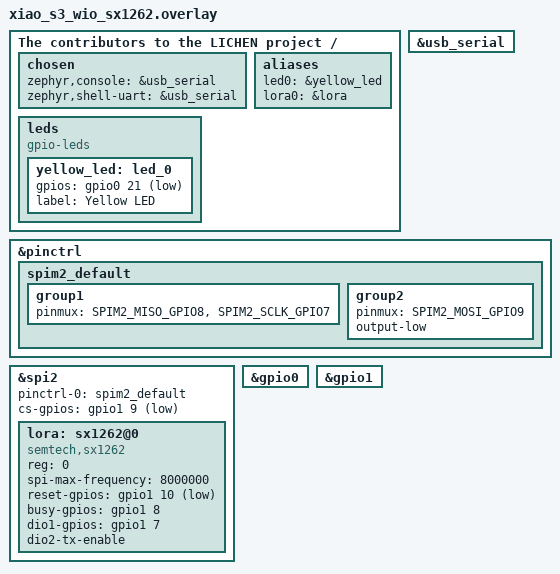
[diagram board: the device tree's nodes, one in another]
# SPDX-License-Identifier: GPL-3.0-or-later
# SPDX-FileCopyrightText: The contributors to the LICHEN project
/*
 * RETIRED/BLOCKED per project-LICHEN-2u26.10 (m5m1.8 bridge audit, project-LICHEN-p70q/worktree-worker18): Seeed XIAO ESP32-S3 + Wio-SX1262 has no canonical Zephyr board target. xiao_s3_wio_sx1262 invalid -b target. Classified FAIL; support removed. Use heltec_wifi_lora32_v3_esp32s3_procpu proxy. Fragment retained for reference only. See docs/firmware-board-capability-matrix.md.
 *
 * Original pin map (for reference):
 * ESP32-S3 + SX1262 LoRa (via B2B connector)
 * SX1262 SPI: SCK=GPIO7, MISO=GPIO8, MOSI=GPIO9, NSS=GPIO41
 * Control: RESET=GPIO42, BUSY=GPIO40, DIO1=GPIO39
 * LED: GPIO21 yellow active-low
 */

#include <zephyr/dt-bindings/pinctrl/esp32s3-pinctrl.h>

/ {
	chosen {
		zephyr,console = &usb_serial;
		zephyr,shell-uart = &usb_serial;
	};

	aliases {
		led0 = &yellow_led;
		lora0 = &lora;
	};

	leds {
		compatible = "gpio-leds";
		yellow_led: led_0 {
			gpios = <&gpio0 21 GPIO_ACTIVE_LOW>;
			label = "Yellow LED";
		};
	};
};

&usb_serial {
	status = "okay";
};

&pinctrl {
	/* SPI2 for SX1262 */
	spim2_default: spim2_default {
		group1 {
			pinmux = <SPIM2_MISO_GPIO8>,
				 <SPIM2_SCLK_GPIO7>;
		};
		group2 {
			pinmux = <SPIM2_MOSI_GPIO9>;
			output-low;
		};
	};
};

&spi2 {
	status = "okay";
	#address-cells = <1>;
	#size-cells = <0>;
	pinctrl-0 = <&spim2_default>;
	pinctrl-names = "default";
	cs-gpios = <&gpio1 9 GPIO_ACTIVE_LOW>;  /* NSS = GPIO41 */

	lora: sx1262@0 {
		compatible = "semtech,sx1262";
		reg = <0>;
		spi-max-frequency = <8000000>;
		reset-gpios = <&gpio1 10 GPIO_ACTIVE_LOW>;  /* RESET = GPIO42 */
		busy-gpios = <&gpio1 8 GPIO_ACTIVE_HIGH>;   /* BUSY = GPIO40 */
		dio1-gpios = <&gpio1 7 GPIO_ACTIVE_HIGH>;   /* DIO1 = GPIO39 */
		dio2-tx-enable;
	};
};

&gpio0 {
	status = "okay";
};

&gpio1 {
	status = "okay";
};
